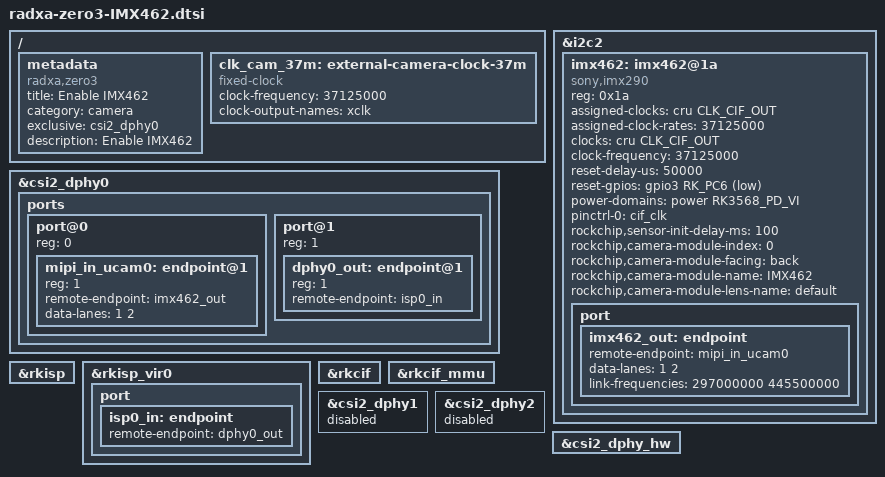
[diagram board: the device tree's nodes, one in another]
// SPDX-License-Identifier: (GPL-2.0+ OR MIT)
/ {
	metadata {
		title = "Enable IMX462";
		compatible = "radxa,zero3";
		category = "camera";
		exclusive = "csi2_dphy0";
		description = "Enable IMX462";
	};
};

/ {
	clk_cam_37m: external-camera-clock-37m {
		compatible = "fixed-clock";
		clock-frequency = <37125000>;
		#clock-cells = <0>;
		clock-output-names = "xclk";
	};
};

&i2c2 {
	status = "okay";

	imx462: imx462@1a {
		status = "okay";

		compatible = "sony,imx290";
		reg = <0x1a>;

		
		clock-names = "xclk";
		assigned-clocks = <&cru CLK_CIF_OUT>;
		assigned-clock-rates = <37125000>;
		clocks = <&cru CLK_CIF_OUT>;
		clock-frequency = <37125000>;
		reset-delay-us = <50000>;
		reset-gpios = <&gpio3 RK_PC6 GPIO_ACTIVE_LOW>; 
		power-domains = <&power RK3568_PD_VI>;
		pinctrl-names = "default";
        	pinctrl-0 = <&cif_clk>;
		rockchip,sensor-init-delay-ms = <100>;
		
		rockchip,camera-module-index = <0>;
		rockchip,camera-module-facing = "back";
		rockchip,camera-module-name = "IMX462";
		rockchip,camera-module-lens-name = "default";

		port {
			imx462_out: endpoint {
				remote-endpoint = <&mipi_in_ucam0>;
				data-lanes = <1 2>;
				link-frequencies = /bits/ 64 <297000000 445500000>; 
			};
		};
	};
};

&csi2_dphy0 {
	status = "okay";

	ports {
		#address-cells = <1>;
		#size-cells = <0>;

		port@0 {
			reg = <0>;
			#address-cells = <1>;
			#size-cells = <0>;

			mipi_in_ucam0: endpoint@1 {
				reg = <1>;
				remote-endpoint = <&imx462_out>;
				data-lanes = <1 2>;
			};
		};

		port@1 {
			reg = <1>;
			#address-cells = <1>;
			#size-cells = <0>;

			dphy0_out: endpoint@1 {
				reg = <1>;
				remote-endpoint = <&isp0_in>;
			};
		};
	};
};

&rkisp {
	status = "okay";
};

&rkisp_vir0 {
	status = "okay";

	port {
		isp0_in: endpoint {
			remote-endpoint = <&dphy0_out>;
		};
	};
};

&rkcif {
	status = "okay";
};

&rkcif_mmu {
	status = "okay";
};

&csi2_dphy1 {
	status = "disabled";
};

&csi2_dphy2 {
	status = "disabled";
};

&csi2_dphy_hw {
	status = "okay";
};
